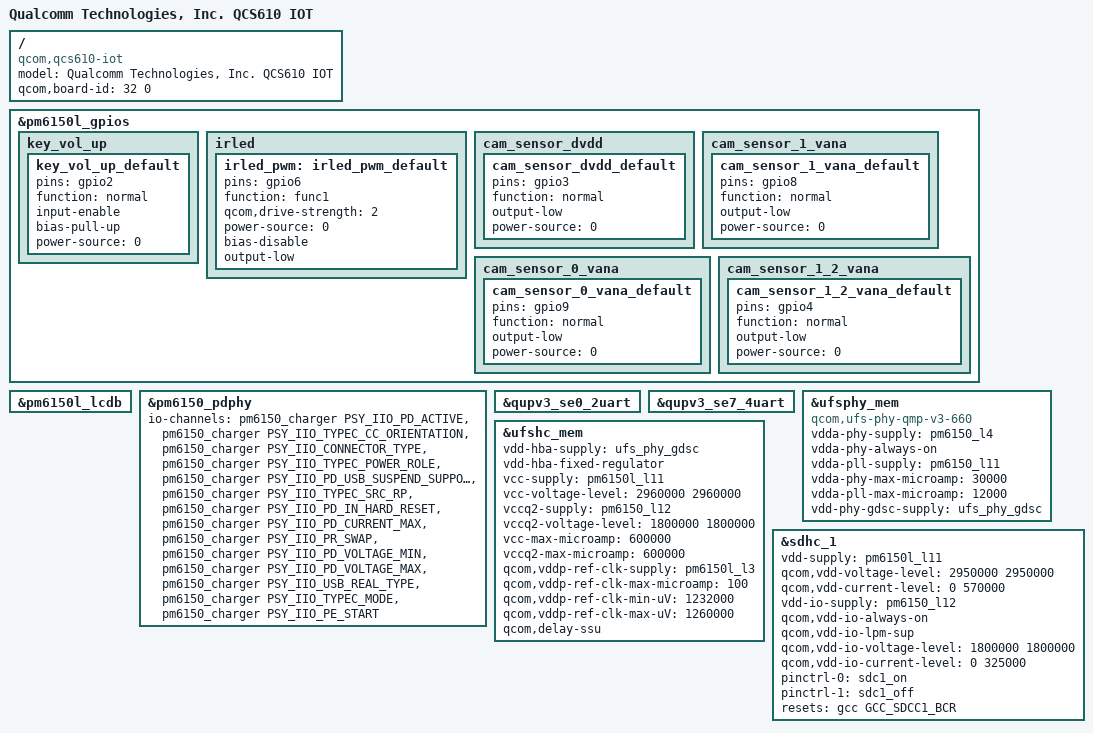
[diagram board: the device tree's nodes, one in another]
// SPDX-License-Identifier: BSD-3-Clause
/*
 * Copyright (c) 2025 Qualcomm Innovation Center, Inc. All rights reserved.
 */

#include <dt-bindings/clock/qcom,gcc-sm6150.h>
#include <dt-bindings/iio/qti_power_supply_iio.h>

/ {
	model = "Qualcomm Technologies, Inc. QCS610 IOT";
	compatible = "qcom,qcs610-iot", "qcom,qcs610", "qcom,iot";
	qcom,board-id = <32 0>;
};

&pm6150l_gpios {
	key_vol_up {
		key_vol_up_default: key_vol_up_default {
			pins = "gpio2";
			function = "normal";
			input-enable;
			bias-pull-up;
			power-source = <0>;
		};
	};

	irled {
		irled_pwm: irled_pwm_default {
			pins = "gpio6";
			function = "func1";
			qcom,drive-strength = <2>;
			power-source = <0>;
			bias-disable;
			output-low;
		};
	};

	cam_sensor_dvdd {
		cam_sensor_dvdd_default: cam_sensor_dvdd_default {
			pins = "gpio3";
			function = "normal";
			output-low;
			power-source = <0>;
		};
	};

	cam_sensor_1_vana {
		cam_sensor_1_vana_default: cam_sensor_1_vana_default {
			pins = "gpio8";
			function = "normal";
			output-low;
			power-source = <0>;
		};
	};

	cam_sensor_0_vana {
		cam_sensor_0_vana_default: cam_sensor_0_vana_default {
			pins = "gpio9";
			function = "normal";
			output-low;
			power-source = <0>;
		};
	};

	cam_sensor_1_2_vana {
		cam_sensor_1_2_vana_default: cam_sensor_1_2_vana_default {
			pins = "gpio4";
			function = "normal";
			output-low;
			power-source = <0>;
		};
	};
};

&pm6150l_lcdb {
        status = "ok";
};

&pm6150_pdphy {
	#io-channel-cells = <1>;
	io-channels = <&pm6150_charger PSY_IIO_PD_ACTIVE>,
		      <&pm6150_charger PSY_IIO_TYPEC_CC_ORIENTATION>,
		      <&pm6150_charger PSY_IIO_CONNECTOR_TYPE>,
		      <&pm6150_charger PSY_IIO_TYPEC_POWER_ROLE>,
		      <&pm6150_charger PSY_IIO_PD_USB_SUSPEND_SUPPORTED>,
		      <&pm6150_charger PSY_IIO_TYPEC_SRC_RP>,
		      <&pm6150_charger PSY_IIO_PD_IN_HARD_RESET>,
		      <&pm6150_charger PSY_IIO_PD_CURRENT_MAX>,
		      <&pm6150_charger PSY_IIO_PR_SWAP>,
		      <&pm6150_charger PSY_IIO_PD_VOLTAGE_MIN>,
		      <&pm6150_charger PSY_IIO_PD_VOLTAGE_MAX>,
		      <&pm6150_charger PSY_IIO_USB_REAL_TYPE>,
		      <&pm6150_charger PSY_IIO_TYPEC_MODE>,
		      <&pm6150_charger PSY_IIO_PE_START>;
	io-channel-names = "pd_active",
			   "typec_cc_orientation",
			   "connector_type",
			   "typec_power_role",
			   "pd_usb_suspend_supported",
			   "typec_src_rp",
			   "pd_in_hard_reset",
			   "pr_current_max",
			   "pr_swap",
			   "pd_voltage_min",
			   "pd_voltage_max",
			   "real_type",
			   "typec_mode",
			   "pe_start";
};

&qupv3_se0_2uart {
	status = "ok";
};

&qupv3_se7_4uart {
        status = "ok";
};

&ufsphy_mem {
	//compatible = "qcom,ufs-phy-qmp-v4-pineapple";
	compatible = "qcom,ufs-phy-qmp-v3-660";

	vdda-phy-supply = <&pm6150_l4>; /* 0.9v */
	vdda-phy-always-on;
	vdda-pll-supply = <&pm6150_l11>;
	vdda-phy-max-microamp = <30000>;
	vdda-pll-max-microamp = <12000>;

	vdd-phy-gdsc-supply = <&ufs_phy_gdsc>;

	status = "ok";
};

&ufshc_mem {
	vdd-hba-supply = <&ufs_phy_gdsc>;
	vdd-hba-fixed-regulator;
	vcc-supply = <&pm6150l_l11>;
	vcc-voltage-level = <2960000 2960000>;
	vccq2-supply = <&pm6150_l12>;
	vccq2-voltage-level = <1800000 1800000>;
	vcc-max-microamp = <600000>;
	vccq2-max-microamp = <600000>;

	qcom,vddp-ref-clk-supply = <&pm6150l_l3>;
	qcom,vddp-ref-clk-max-microamp = <100>;
	qcom,vddp-ref-clk-min-uV = <1232000>;
	qcom,vddp-ref-clk-max-uV = <1260000>;

	/*
	 * QCS610 UFS 3.x uses PMIC Buck regulator which requires additional
	 * delay to settle its voltage back to normal 2.5volts from
	 * the power down, so below property is used to enable delay
	 * before sending start stop unit command.
	 */
	qcom,delay-ssu;

	status = "ok";
};

&sdhc_1 {
	vdd-supply = <&pm6150l_l11>;
	qcom,vdd-voltage-level = <2950000 2950000>;
	qcom,vdd-current-level = <0 570000>;

	vdd-io-supply = <&pm6150_l12>;
	qcom,vdd-io-always-on;
	qcom,vdd-io-lpm-sup;
	qcom,vdd-io-voltage-level = <1800000 1800000>;
	qcom,vdd-io-current-level = <0 325000>;

	pinctrl-names = "default", "sleep";
	pinctrl-0 = <&sdc1_on>;
	pinctrl-1 = <&sdc1_off>;

	resets = <&gcc GCC_SDCC1_BCR>;
	reset-names = "core_reset";

	status = "ok";
};
